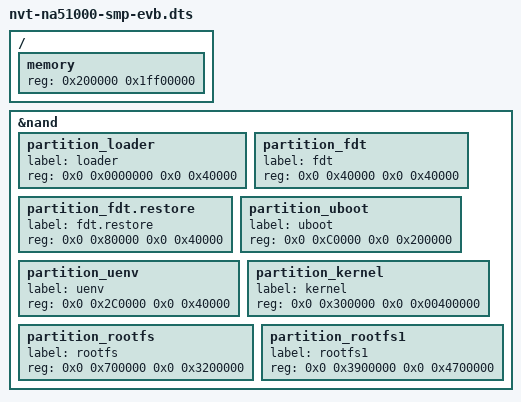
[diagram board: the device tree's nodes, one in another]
/*
 * Novatek Ltd. NA51000 BSP part of dts
 *
 * Cortex-A53 MPCore
 *
 */

/dts-v1/;

#include <dt-bindings/gpio/nvt-gpio.h>
#include "nvt-na51000-peri.dtsi"
#include "nvt-na51000-media.dtsi"
#include "nvt-na51000-top.dtsi"

/ {
	memory {						/* Linux system memory region*/
		device_type = "memory";
		reg = <0x200000 0x1ff00000>;
	};
};

&nand {
	partition_loader {					/* Fixed */
		label = "loader";
		reg = <0x0 0x0000000 0x0 0x40000>;
	};

	partition_fdt {						/* Fixed */
		label = "fdt";
		reg = <0x0 0x40000 0x0 0x40000>;
	};

	partition_fdt.restore {					/* Fixed */
		label = "fdt.restore";
		reg = <0x0 0x80000 0x0 0x40000>;
	};

	partition_uboot {
		label = "uboot";
		reg = <0x0 0xC0000 0x0 0x200000>;
	};

	partition_uenv {
		label = "uenv";
		reg = <0x0 0x2C0000 0x0 0x40000>;
	};

	partition_kernel {
		label = "kernel";
		reg = <0x0 0x300000 0x0 0x00400000>;
	};

	partition_rootfs {
		label = "rootfs";
		reg = <0x0 0x700000 0x0 0x3200000>;
	};

	partition_rootfs1 {
		label = "rootfs1";
		reg = <0x0 0x3900000 0x0 0x4700000>;
	};
};
